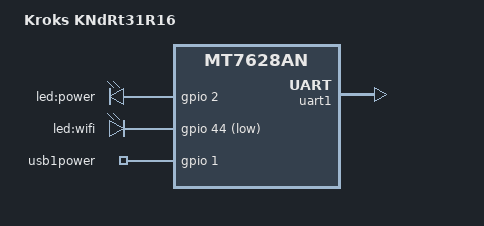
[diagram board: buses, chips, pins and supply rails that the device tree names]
#include "mt7628an_kroks_5eth.dtsi"

/ {
	compatible = "kroks,kndrt31r16", "mediatek,mt7628an-soc";
	model = "Kroks KNdRt31R16";

	aliases {
		led-boot = &led_power;
		led-failsafe = &led_power;
		led-running = &led_power;
		led-upgrade = &led_power;
		serial1 = &uart1;
	};

	leds {
		compatible = "gpio-leds";

		led_power: power {
			label = "led:power";
			gpios = <&gpio 2 GPIO_ACTIVE_HIGH>;
		};

		wifi {
			label = "led:wifi";
			gpios = <&gpio 44 GPIO_ACTIVE_LOW>;
			linux,default-trigger = "phy0tpt";
		};
	};

	gpio_export {
		compatible = "gpio-export";
		#size-cells = <0>;

		usb1power {
			gpio-export,name = "usb1power";
			gpio-export,output = <1>;
			gpios = <&gpio 1 GPIO_ACTIVE_HIGH>;
		};
	};
};

&uart1 {
	status = "okay";
};

&state_default {
	gpio {
		groups = "i2s", "wled_an";
		function = "gpio";
	};
};
